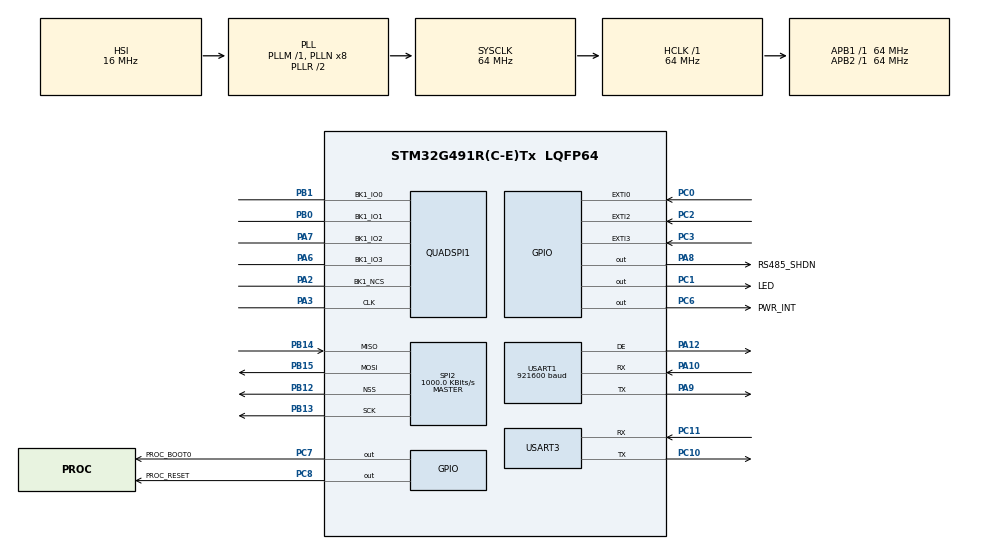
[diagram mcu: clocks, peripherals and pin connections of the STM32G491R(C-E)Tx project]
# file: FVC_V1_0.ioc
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Mcu.Family=STM32G4
Mcu.Name=STM32G491R(C-E)Tx
Mcu.Package=LQFP64
NVIC.EXTI0_IRQn=true\:0\:0\:false\:false\:true\:true\:true\:true
NVIC.EXTI2_IRQn=true\:0\:0\:false\:false\:true\:true\:true\:true
NVIC.EXTI3_IRQn=true\:0\:0\:false\:false\:true\:true\:true\:true
NVIC.PriorityGroup=NVIC_PRIORITYGROUP_4
NVIC.TIM1_UP_TIM16_IRQn=true\:0\:0\:false\:false\:true\:true\:true\:true
NVIC.TIM2_IRQn=true\:0\:0\:false\:false\:true\:true\:true\:true
NVIC.USART1_IRQn=true\:0\:0\:false\:false\:true\:true\:true\:true
PA10.GPIO_Speed=GPIO_SPEED_FREQ_VERY_HIGH
PA10.Mode=Asynchronous
PA10.Signal=USART1_RX
PA12.GPIO_Speed=GPIO_SPEED_FREQ_VERY_HIGH
PA12.Mode=Hardware Flow Control (RS485)
PA12.Signal=USART1_DE
PA13.Mode=Serial_Wire
PA13.Signal=SYS_JTMS-SWDIO
PA14.Mode=Serial_Wire
PA14.Signal=SYS_JTCK-SWCLK
PA2.GPIO_Speed=GPIO_SPEED_FREQ_VERY_HIGH
PA2.Mode=Single Bank 1
PA2.Signal=QUADSPI1_BK1_NCS
PA3.GPIO_Speed=GPIO_SPEED_FREQ_VERY_HIGH
PA3.Mode=Single Bank 1
PA3.Signal=QUADSPI1_CLK
PA6.GPIO_Speed=GPIO_SPEED_FREQ_VERY_HIGH
PA6.Mode=Single Bank 1
PA6.Signal=QUADSPI1_BK1_IO3
PA7.GPIO_Speed=GPIO_SPEED_FREQ_VERY_HIGH
PA7.Mode=Single Bank 1
PA7.Signal=QUADSPI1_BK1_IO2
PA8.GPIO_Label=RS485_SHDN
PA8.PinState=GPIO_PIN_SET
PA8.Signal=GPIO_Output
PA9.GPIO_Speed=GPIO_SPEED_FREQ_VERY_HIGH
PA9.Mode=Asynchronous
PA9.Signal=USART1_TX
PB0.GPIO_Speed=GPIO_SPEED_FREQ_VERY_HIGH
PB0.Mode=Single Bank 1
PB0.Signal=QUADSPI1_BK1_IO1
PB1.GPIO_Speed=GPIO_SPEED_FREQ_VERY_HIGH
PB1.Mode=Single Bank 1
PB1.Signal=QUADSPI1_BK1_IO0
PB12.Mode=NSS_Signal_Hard_Output
PB12.Signal=SPI2_NSS
PB13.Mode=Full_Duplex_Master
PB13.Signal=SPI2_SCK
PB14.Mode=Full_Duplex_Master
PB14.Signal=SPI2_MISO
PB15.Mode=Full_Duplex_Master
PB15.Signal=SPI2_MOSI
PC0.Signal=GPXTI0
PC1.GPIO_Label=LED
PC1.Signal=GPIO_Output
PC10.Mode=Asynchronous
PC10.Signal=USART3_TX
PC11.Mode=Asynchronous
PC11.Signal=USART3_RX
PC2.Signal=GPXTI2
PC3.Signal=GPXTI3
PC6.GPIO_Label=PWR_INT
PC6.Signal=GPIO_Output
PC7.GPIO_Label=PROC_BOOT0
PC7.Signal=GPIO_Output
PC8.GPIO_Label=PROC_RESET
PC8.Signal=GPIO_Output
ProjectManager.HeapSize=0x200
ProjectManager.StackSize=0x400
ProjectManager.TargetToolchain=STM32CubeIDE
QUADSPI1.ChipSelectHighTime=QSPI_CS_HIGH_TIME_6_CYCLE
QUADSPI1.FlashSize=19
RCC.ADC12Freq_Value=64000000
RCC.ADC345Freq_Value=64000000
RCC.AHBFreq_Value=64000000
RCC.APB1Freq_Value=64000000
RCC.APB1TimFreq_Value=64000000
RCC.APB2Freq_Value=64000000
RCC.APB2TimFreq_Value=64000000
RCC.CortexFreq_Value=64000000
RCC.EXTERNAL_CLOCK_VALUE=12288000
RCC.HCLKFreq_Value=64000000
RCC.HSE_VALUE=8000000
RCC.HSI48_VALUE=48000000
RCC.HSI_VALUE=16000000
RCC.LSE_VALUE=32768
RCC.SYSCLKFreq_VALUE=64000000
RCC.SYSCLKSource=RCC_SYSCLKSOURCE_PLLCLK
RCC.USBFreq_Value=48000000
RCC.VCOOutputFreq_Value=128000000
SPI2.BaudRatePrescaler=SPI_BAUDRATEPRESCALER_64
SPI2.CalculateBaudRate=1000.0 KBits/s
SPI2.Direction=SPI_DIRECTION_2LINES
SPI2.Mode=SPI_MODE_MASTER
SPI2.VirtualNSS=VM_NSSHARD
SPI2.VirtualType=VM_MASTER
TIM1.CounterMode=TIM_COUNTERMODE_DOWN
TIM1.Prescaler=63999
TIM2.CounterMode=TIM_COUNTERMODE_DOWN
TIM2.Prescaler=63999
USART1.BaudRate=921600
USART1.VirtualMode-Asynchronous=VM_ASYNC
USART1.VirtualMode-Hardware\ Flow\ Control\ (RS485)=VM_ASYNC
USART3.VirtualMode-Asynchronous=VM_ASYNC
VP_CRC_VS_CRC.Mode=CRC_Activate
VP_TIM1_VS_ClockSourceINT.Mode=Internal
VP_TIM2_VS_ClockSourceINT.Mode=Internal
board=custom

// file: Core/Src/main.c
/* USER CODE BEGIN Header */
/**
  ******************************************************************************
  * @file           : main.c
  * @brief          : Main program body
  ******************************************************************************
  * @attention
  *
  * Copyright (c) 2023 STMicroelectronics.
  * All rights reserved.
  *
  * This software is licensed under terms that can be found in the LICENSE file
  * in the root directory of this software component.
  * If no LICENSE file comes with this software, it is provided AS-IS.
  *
  ******************************************************************************
  */
/* USER CODE END Header */
#include "main.h"
#include "crc.h"
#include "quadspi.h"
#include "spi.h"
#include "tim.h"
#include "usart.h"
#include "gpio.h"

/* USER CODE BEGIN Includes */
#include "fvc.h"
/* USER CODE END Includes */

void SystemClock_Config(void);

int main(void)
{

  /* MCU Configuration--------------------------------------------------------*/

  /* Reset of all peripherals, Initializes the Flash interface and the Systick. */
  HAL_Init();

  /* Configure the system clock */
  SystemClock_Config();

  /* Initialize all configured peripherals */
  MX_GPIO_Init();
  MX_QUADSPI1_Init();
  MX_USART1_UART_Init();
  MX_SPI2_Init();
  MX_USART3_UART_Init();
  MX_CRC_Init();
  MX_TIM1_Init();
  MX_TIM2_Init();
  /* USER CODE BEGIN 2 */
  fvc_main();
  /* USER CODE END 2 */

  /* Infinite loop */
  while (1)
  {

  }
}

void SystemClock_Config(void)
{
  RCC_OscInitTypeDef RCC_OscInitStruct = {0};
  RCC_ClkInitTypeDef RCC_ClkInitStruct = {0};

  /** Configure the main internal regulator output voltage
  */
  HAL_PWREx_ControlVoltageScaling(PWR_REGULATOR_VOLTAGE_SCALE1);

  /** Initializes the RCC Oscillators according to the specified parameters
  * in the RCC_OscInitTypeDef structure.
  */
  RCC_OscInitStruct.OscillatorType = RCC_OSCILLATORTYPE_HSI;
  RCC_OscInitStruct.HSIState = RCC_HSI_ON;
  RCC_OscInitStruct.HSICalibrationValue = RCC_HSICALIBRATION_DEFAULT;
  RCC_OscInitStruct.PLL.PLLState = RCC_PLL_ON;
  RCC_OscInitStruct.PLL.PLLSource = RCC_PLLSOURCE_HSI;
  RCC_OscInitStruct.PLL.PLLM = RCC_PLLM_DIV1;
  RCC_OscInitStruct.PLL.PLLN = 8;
  RCC_OscInitStruct.PLL.PLLP = RCC_PLLP_DIV2;
  RCC_OscInitStruct.PLL.PLLQ = RCC_PLLQ_DIV2;
  RCC_OscInitStruct.PLL.PLLR = RCC_PLLR_DIV2;
  if (HAL_RCC_OscConfig(&RCC_OscInitStruct) != HAL_OK)
  {
    Error_Handler();
  }

  /** Initializes the CPU, AHB and APB buses clocks
  */
  RCC_ClkInitStruct.ClockType = RCC_CLOCKTYPE_HCLK|RCC_CLOCKTYPE_SYSCLK
                              |RCC_CLOCKTYPE_PCLK1|RCC_CLOCKTYPE_PCLK2;
  RCC_ClkInitStruct.SYSCLKSource = RCC_SYSCLKSOURCE_PLLCLK;
  RCC_ClkInitStruct.AHBCLKDivider = RCC_SYSCLK_DIV1;
  RCC_ClkInitStruct.APB1CLKDivider = RCC_HCLK_DIV1;
  RCC_ClkInitStruct.APB2CLKDivider = RCC_HCLK_DIV1;

  if (HAL_RCC_ClockConfig(&RCC_ClkInitStruct, FLASH_LATENCY_2) != HAL_OK)
  {
    Error_Handler();
  }
}

void Error_Handler(void)
{
  __disable_irq();
  while (1)
  {
  }
}
